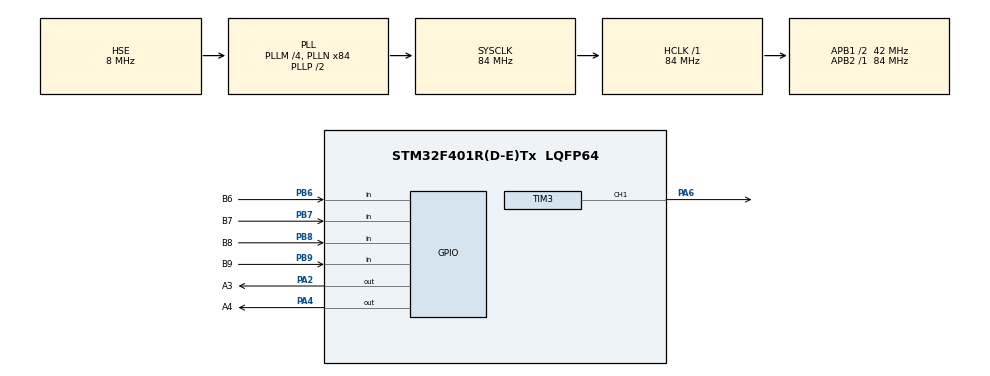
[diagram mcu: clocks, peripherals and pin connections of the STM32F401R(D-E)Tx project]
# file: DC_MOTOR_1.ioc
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Mcu.Family=STM32F4
Mcu.Name=STM32F401R(D-E)Tx
Mcu.Package=LQFP64
NVIC.PriorityGroup=NVIC_PRIORITYGROUP_4
PA2.GPIO_Label=A3
PA2.Signal=GPIO_Output
PA4.GPIO_Label=A4
PA4.Signal=GPIO_Output
PA6.Signal=S_TIM3_CH1
PB6.GPIO_Label=B6
PB6.GPIO_PuPd=GPIO_PULLUP
PB6.Signal=GPIO_Input
PB7.GPIO_Label=B7
PB7.GPIO_PuPd=GPIO_PULLUP
PB7.Signal=GPIO_Input
PB8.GPIO_Label=B8
PB8.GPIO_PuPd=GPIO_PULLUP
PB8.Signal=GPIO_Input
PB9.GPIO_Label=B9
PB9.GPIO_PuPd=GPIO_PULLUP
PB9.Signal=GPIO_Input
PH0\ -\ OSC_IN.Mode=HSE-External-Oscillator
PH0\ -\ OSC_IN.Signal=RCC_OSC_IN
PH1\ -\ OSC_OUT.Mode=HSE-External-Oscillator
PH1\ -\ OSC_OUT.Signal=RCC_OSC_OUT
ProjectManager.HeapSize=0x200
ProjectManager.StackSize=0x400
ProjectManager.TargetToolchain=STM32CubeIDE
RCC.48MHZClocksFreq_Value=42000000
RCC.AHBFreq_Value=84000000
RCC.APB1CLKDivider=RCC_HCLK_DIV2
RCC.APB1Freq_Value=42000000
RCC.APB1TimFreq_Value=84000000
RCC.APB2Freq_Value=84000000
RCC.APB2TimFreq_Value=84000000
RCC.CortexFreq_Value=84000000
RCC.HCLKFreq_Value=84000000
RCC.HSE_VALUE=8000000
RCC.HSI_VALUE=16000000
RCC.LSE_VALUE=32768
RCC.PLLM=4
RCC.PLLN=84
RCC.PLLSourceVirtual=RCC_PLLSOURCE_HSE
RCC.SYSCLKFreq_VALUE=84000000
RCC.SYSCLKSource=RCC_SYSCLKSOURCE_PLLCLK
RCC.VCOOutputFreq_Value=168000000
SH.S_TIM3_CH1.0=TIM3_CH1,PWM Generation1 CH1
TIM3.Channel-PWM\ Generation1\ CH1=TIM_CHANNEL_1
TIM3.Period=19999
TIM3.Prescaler=84-1
board=custom

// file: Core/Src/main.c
/* USER CODE BEGIN Header */
/**
  ******************************************************************************
  * @file           : main.c
  * @brief          : Main program body
  ******************************************************************************
  * @attention
  *
  * Copyright (c) 2022 STMicroelectronics.
  * All rights reserved.
  *
  * This software is licensed under terms that can be found in the LICENSE file
  * in the root directory of this software component.
  * If no LICENSE file comes with this software, it is provided AS-IS.
  *
  ******************************************************************************
  */
/* USER CODE END Header */
#include "main.h"

/* USER CODE BEGIN Includes */
#include "stm32f4xx_hal.h"

/* USER CODE END Includes */

 TIM_HandleTypeDef htim3;

void SystemClock_Config(void);
static void MX_GPIO_Init(void);
static void MX_TIM3_Init(void);

int main(void)
{

  /* MCU Configuration--------------------------------------------------------*/

  /* Reset of all peripherals, Initializes the Flash interface and the Systick. */
  HAL_Init();

  /* Configure the system clock */
  SystemClock_Config();

  /* Initialize all configured peripherals */
  MX_GPIO_Init();
  MX_TIM3_Init();
  /* USER CODE BEGIN 2 */

  HAL_GPIO_WritePin(GPIOA,A3_Pin,GPIO_PIN_SET);   // Start first motor clock wise rotation
  HAL_GPIO_WritePin(GPIOA,A4_Pin,GPIO_PIN_RESET);
  HAL_TIM_Base_Start(&htim3);               //Initialize stm32 timer 3
  HAL_TIM_PWM_Start(&htim3,TIM_CHANNEL_1);  //PB0 Start pwm second motor 100% duty cycle
  /* USER CODE END 2 */

  /* Infinite loop */
  while (1)
  {

    /* USER CODE BEGIN 3 */
	  //Change direction of motors anti clock wise

	 		if(HAL_GPIO_ReadPin(GPIOB,B9_Pin)==GPIO_PIN_RESET)
	 		{
	 				HAL_GPIO_TogglePin(GPIOA,A3_Pin);
	 			      //  HAL_Delay(3000); //Delay for 3 seconds to stop motor properly
	 				HAL_GPIO_TogglePin(GPIOA,A4_Pin);
	 		}
	 		if(HAL_GPIO_ReadPin(GPIOB,B8_Pin)==GPIO_PIN_RESET) //Motor rotate at 75% duty cycle
	 				{
	 					__HAL_TIM_SET_COMPARE(&htim3,TIM_CHANNEL_1,75); //Second motor 75% voltage

	 				}

	 				if(HAL_GPIO_ReadPin(GPIOB,B7_Pin)==GPIO_PIN_RESET) //Motor rotate at 50% duty cycle
	 				{
	 					__HAL_TIM_SET_COMPARE(&htim3,TIM_CHANNEL_1,50); //Second motor 50% voltage
	 					//__HAL_TIM_SET_COMPARE(&htim3,TIM_CHANNEL_4,50); //Second motor 50% voltage
	 				}

	 				if(HAL_GPIO_ReadPin(GPIOB,B6_Pin)==GPIO_PIN_RESET) //Motor rotate at 25% duty cycle
	 				{
	 					__HAL_TIM_SET_COMPARE(&htim3,TIM_CHANNEL_1,25); //Second motor 25% voltage
	 					//__HAL_TIM_SET_COMPARE(&htim3,TIM_CHANNEL_4,25); //Second motor 25% voltage
	 				}
  }
  /* USER CODE END 3 */
}

void SystemClock_Config(void)
{
  RCC_OscInitTypeDef RCC_OscInitStruct = {0};
  RCC_ClkInitTypeDef RCC_ClkInitStruct = {0};

  /** Configure the main internal regulator output voltage
  */
  __HAL_RCC_PWR_CLK_ENABLE();
  __HAL_PWR_VOLTAGESCALING_CONFIG(PWR_REGULATOR_VOLTAGE_SCALE2);

  /** Initializes the RCC Oscillators according to the specified parameters
  * in the RCC_OscInitTypeDef structure.
  */
  RCC_OscInitStruct.OscillatorType = RCC_OSCILLATORTYPE_HSE;
  RCC_OscInitStruct.HSEState = RCC_HSE_ON;
  RCC_OscInitStruct.PLL.PLLState = RCC_PLL_ON;
  RCC_OscInitStruct.PLL.PLLSource = RCC_PLLSOURCE_HSE;
  RCC_OscInitStruct.PLL.PLLM = 4;
  RCC_OscInitStruct.PLL.PLLN = 84;
  RCC_OscInitStruct.PLL.PLLP = RCC_PLLP_DIV2;
  RCC_OscInitStruct.PLL.PLLQ = 4;
  if (HAL_RCC_OscConfig(&RCC_OscInitStruct) != HAL_OK)
  {
    Error_Handler();
  }

  /** Initializes the CPU, AHB and APB buses clocks
  */
  RCC_ClkInitStruct.ClockType = RCC_CLOCKTYPE_HCLK|RCC_CLOCKTYPE_SYSCLK
                              |RCC_CLOCKTYPE_PCLK1|RCC_CLOCKTYPE_PCLK2;
  RCC_ClkInitStruct.SYSCLKSource = RCC_SYSCLKSOURCE_PLLCLK;
  RCC_ClkInitStruct.AHBCLKDivider = RCC_SYSCLK_DIV1;
  RCC_ClkInitStruct.APB1CLKDivider = RCC_HCLK_DIV2;
  RCC_ClkInitStruct.APB2CLKDivider = RCC_HCLK_DIV1;

  if (HAL_RCC_ClockConfig(&RCC_ClkInitStruct, FLASH_LATENCY_2) != HAL_OK)
  {
    Error_Handler();
  }
}

static void MX_TIM3_Init(void)
{

  TIM_MasterConfigTypeDef sMasterConfig = {0};
  TIM_OC_InitTypeDef sConfigOC = {0};

  htim3.Instance = TIM3;
  htim3.Init.Prescaler = 84-1;
  htim3.Init.CounterMode = TIM_COUNTERMODE_UP;
  htim3.Init.Period = 19999;
  htim3.Init.ClockDivision = TIM_CLOCKDIVISION_DIV1;
  htim3.Init.AutoReloadPreload = TIM_AUTORELOAD_PRELOAD_DISABLE;
  if (HAL_TIM_PWM_Init(&htim3) != HAL_OK)
  {
    Error_Handler();
  }
  sMasterConfig.MasterOutputTrigger = TIM_TRGO_RESET;
  sMasterConfig.MasterSlaveMode = TIM_MASTERSLAVEMODE_DISABLE;
  if (HAL_TIMEx_MasterConfigSynchronization(&htim3, &sMasterConfig) != HAL_OK)
  {
    Error_Handler();
  }
  sConfigOC.OCMode = TIM_OCMODE_PWM1;
  sConfigOC.Pulse = 0;
  sConfigOC.OCPolarity = TIM_OCPOLARITY_HIGH;
  sConfigOC.OCFastMode = TIM_OCFAST_DISABLE;
  if (HAL_TIM_PWM_ConfigChannel(&htim3, &sConfigOC, TIM_CHANNEL_1) != HAL_OK)
  {
    Error_Handler();
  }
  HAL_TIM_MspPostInit(&htim3);

}

static void MX_GPIO_Init(void)
{
  GPIO_InitTypeDef GPIO_InitStruct = {0};

  /* GPIO Ports Clock Enable */
  __HAL_RCC_GPIOH_CLK_ENABLE();
  __HAL_RCC_GPIOA_CLK_ENABLE();
  __HAL_RCC_GPIOB_CLK_ENABLE();

  /*Configure GPIO pin Output Level */
  HAL_GPIO_WritePin(GPIOA, A3_Pin|A4_Pin, GPIO_PIN_RESET);

  /*Configure GPIO pins : A3_Pin A4_Pin */
  GPIO_InitStruct.Pin = A3_Pin|A4_Pin;
  GPIO_InitStruct.Mode = GPIO_MODE_OUTPUT_PP;
  GPIO_InitStruct.Pull = GPIO_NOPULL;
  GPIO_InitStruct.Speed = GPIO_SPEED_FREQ_LOW;
  HAL_GPIO_Init(GPIOA, &GPIO_InitStruct);

  /*Configure GPIO pins : B6_Pin B7_Pin B8_Pin B9_Pin */
  GPIO_InitStruct.Pin = B6_Pin|B7_Pin|B8_Pin|B9_Pin;
  GPIO_InitStruct.Mode = GPIO_MODE_INPUT;
  GPIO_InitStruct.Pull = GPIO_PULLUP;
  HAL_GPIO_Init(GPIOB, &GPIO_InitStruct);

}

void Error_Handler(void)
{
  __disable_irq();
  while (1)
  {
  }
}
